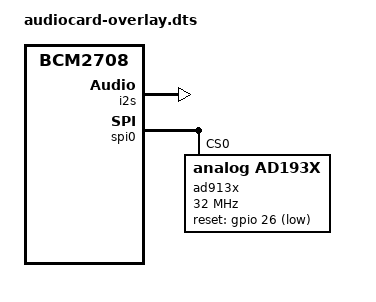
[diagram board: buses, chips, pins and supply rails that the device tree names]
// Definitions for SuperAudioBoard
/dts-v1/;
/plugin/;

/ {
	compatible = "brcm,bcm2708";

	fragment@0 {
		target = <&sound>;
		__overlay__ {
			compatible = "audiocard,audiocard";
			i2s-controller = <&i2s>;
			status = "okay";
		};
	};

	fragment@1 {
		target = <&i2s>;
		__overlay__ {
			status = "okay";
		};
	};
    
    fragment@2 {
        target = <&gpio>;
        __overlay__ {
            audiocard_pins: audiocard_pins {
                brcm,pins = <26>; /* Pin 26 */
                brcm,function = <1>; /* Output */
            };
        };
    };

	fragment@3 {
		target = <&spi0>;
		__overlay__ {
			/* needed to avoid dtc warning */
			#address-cells = <1>;
			#size-cells = <0>;
			status = "okay";

			ad913x: ad193x@0{
				compatible = "analog,ad193x";
				reg = <0>;
				status = "okay";
				reset-gpio = <&gpio 26 1>; /* Pin 26, 1 = active low? */

				pinctrl-names = "default";
				pinctrl-0 = <&audiocard_pins>;
				spi-max-frequency = <32000000>;
			}

		};
	};
    __overrides__ {
        gpiopin = <&cs4271>,"reset-gpio:4",
                  <&audiocard_pins>,"brcm,pins:0";
    };
};
